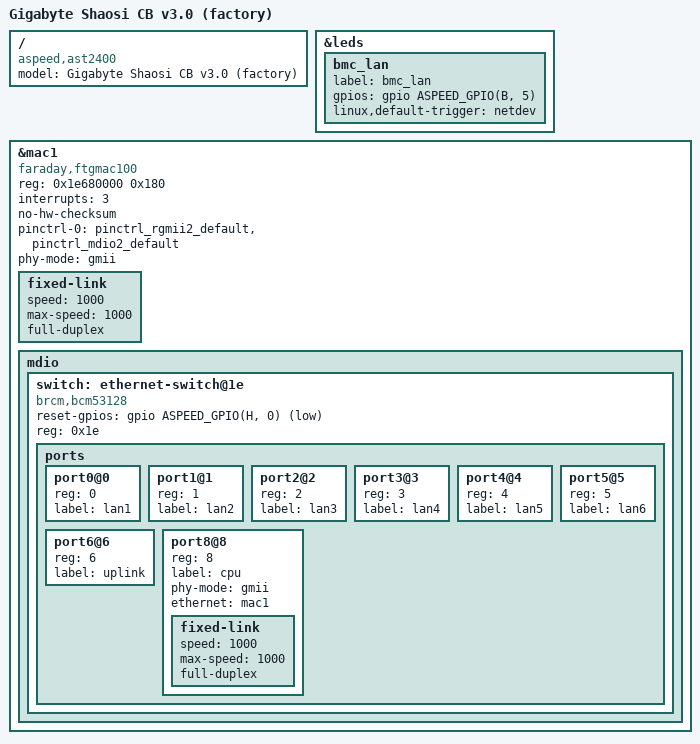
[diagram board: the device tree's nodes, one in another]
/dts-v1/;
/plugin/;

#include <dt-bindings/gpio/gpio.h>
#include <dt-bindings/gpio/aspeed-gpio.h>

/ {
	compatible = "aspeed,ast2400";

	fragment@0 {
		target-path = "/";
		__overlay__ {
			model = "Gigabyte Shaosi CB v3.0 (factory)";
		};
	};

	fragment@1 {
		target = <&leds>;
		__overlay__ {
			bmc_lan {
				label = "bmc_lan";
				gpios = <&gpio ASPEED_GPIO(B, 5) GPIO_ACTIVE_HIGH>;
				linux,default-trigger = "netdev";
			};
		};
	};

	fragment@2 {
		target = <&mac1>;
		#address-cells = <1>;
		#size-cells = <0>;
		__overlay__ {
			#address-cells = <1>;
			#size-cells = <0>;
			compatible = "faraday,ftgmac100", "aspeed,ast2400-mac";
			reg = <0x1e680000 0x180>;
			interrupts = <3>;
			status = "okay";
			no-hw-checksum;

			pinctrl-names = "default";
			pinctrl-0 = <&pinctrl_rgmii2_default &pinctrl_mdio2_default>;

			phy-mode = "gmii";

			fixed-link {
				speed = <1000>;
				max-speed = <1000>;
				full-duplex;
			};

			mdio {
				#address-cells = <1>;
				#size-cells = <0>;

				switch: ethernet-switch@1e {
					#address-cells = <1>;
					#size-cells = <0>;
					compatible = "brcm,bcm53128";
					reset-gpios = <&gpio ASPEED_GPIO(H, 0) GPIO_ACTIVE_LOW>;
					reg = <0x1e>;

					ports {
						port0@0 {
							reg = <0>;
							label = "lan1";
						};

						port1@1 {
							reg = <1>;
							label = "lan2";
						};

						port2@2 {
							reg = <2>;
							label = "lan3";
						};

						port3@3 {
							reg = <3>;
							label = "lan4";
						};

						port4@4 {
							reg = <4>;
							label = "lan5";
						};

						port5@5 {
							reg = <5>;
							label = "lan6";
						};

						port6@6 {
							reg = <6>;
							label = "uplink";
						};

						port8@8 {
							reg = <8>;
							label = "cpu";
							phy-mode = "gmii";
							ethernet = <&mac1>;
							fixed-link {
								speed = <1000>;
								max-speed = <1000>;
								full-duplex;
							};
						};
					};
				};
			};
		};
	};
};
